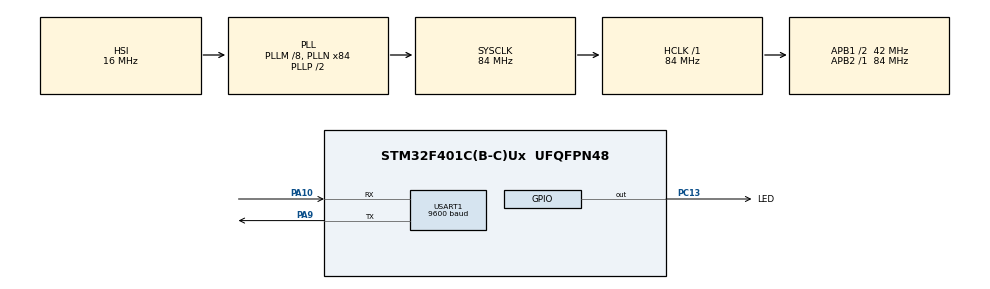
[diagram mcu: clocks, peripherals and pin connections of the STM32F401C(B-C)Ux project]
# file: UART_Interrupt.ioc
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Mcu.Family=STM32F4
RCC.CortexFreq_Value=84000000
PA10.Mode=Asynchronous
PC13-ANTI_TAMP.GPIO_Label=LED
USART1.BaudRate=9600
PH1\ -\ OSC_OUT.Mode=HSE-External-Oscillator
RCC.APB1CLKDivider=RCC_HCLK_DIV2
PC13-ANTI_TAMP.PinState=GPIO_PIN_SET
RCC.SYSCLKSource=RCC_SYSCLKSOURCE_PLLCLK
ProjectManager.StackSize=0x400
PA13.Signal=SYS_JTMS-SWDIO
PA9.Mode=Asynchronous
PH0\ -\ OSC_IN.Mode=HSE-External-Oscillator
VP_SYS_VS_tim10.Mode=TIM10
PH0\ -\ OSC_IN.Signal=RCC_OSC_IN
ProjectManager.TargetToolchain=STM32CubeIDE
RCC.HCLKFreq_Value=84000000
RCC.APB2TimFreq_Value=84000000
PA9.Signal=USART1_TX
RCC.LSE_VALUE=32768
RCC.AHBFreq_Value=84000000
RCC.HSE_VALUE=25000000
PH1\ -\ OSC_OUT.Signal=RCC_OSC_OUT
board=custom
PC13-ANTI_TAMP.Signal=GPIO_Output
RCC.VCOOutputFreq_Value=168000000
RCC.APB2Freq_Value=84000000
PA14.Mode=Serial_Wire
PA13.Mode=Serial_Wire
Mcu.Name=STM32F401C(B-C)Ux
RCC.48MHZClocksFreq_Value=42000000
RCC.SYSCLKFreq_VALUE=84000000
Mcu.Package=UFQFPN48
NVIC.TimeBase=TIM1_UP_TIM10_IRQn
USART1.VirtualMode=VM_ASYNC
NVIC.TimeBaseIP=TIM10
PA10.Signal=USART1_RX
PA14.Signal=SYS_JTCK-SWCLK
ProjectManager.HeapSize=0x200
NVIC.TIM1_UP_TIM10_IRQn=true\:0\:0\:false\:false\:true\:false\:true
RCC.HSI_VALUE=16000000
NVIC.PriorityGroup=NVIC_PRIORITYGROUP_4
RCC.PLLM=8
RCC.PLLN=84
RCC.APB1TimFreq_Value=84000000
NVIC.USART1_IRQn=true\:0\:0\:false\:false\:true\:true\:true
RCC.APB1Freq_Value=42000000

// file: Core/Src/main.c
/* USER CODE BEGIN Header */
/**
  ******************************************************************************
  * @file           : main.c
  * @brief          : Main program body
  ******************************************************************************
  * @attention
  *
  * <h2><center>&copy; Copyright (c) 2021 STMicroelectronics.
  * All rights reserved.</center></h2>
  *
  * This software component is licensed by ST under BSD 3-Clause license,
  * the "License"; You may not use this file except in compliance with the
  * License. You may obtain a copy of the License at:
  *                        opensource.org/licenses/BSD-3-Clause
  *
  ******************************************************************************
  */
/* USER CODE END Header */
#include "main.h"

/* USER CODE BEGIN Includes */
#include <stdio.h>
#include <string.h>
/* USER CODE END Includes */

UART_HandleTypeDef huart1;

/* USER CODE BEGIN PV */
uint8_t rxBuff[50];
/* USER CODE END PV */

void SystemClock_Config(void);
static void MX_GPIO_Init(void);
static void MX_USART1_UART_Init(void);
/* USER CODE BEGIN PFP */
void HAL_UART_RxCpltCallback(UART_HandleTypeDef *huart) {
	if(huart->Instance == huart1.Instance) {
		if(rxBuff[0] == 'o')
			HAL_GPIO_WritePin(LED_GPIO_Port, LED_Pin, GPIO_PIN_RESET);
		if(rxBuff[0] == 'x')
			HAL_GPIO_WritePin(LED_GPIO_Port, LED_Pin, GPIO_PIN_SET);
		HAL_UART_Receive_IT(&huart1, rxBuff, 1);
	}
}
/* USER CODE END PFP */

int main(void)
{

  /* MCU Configuration--------------------------------------------------------*/

  /* Reset of all peripherals, Initializes the Flash interface and the Systick. */
  HAL_Init();

  /* Configure the system clock */
  SystemClock_Config();

  /* Initialize all configured peripherals */
  MX_GPIO_Init();
  MX_USART1_UART_Init();
  /* USER CODE BEGIN 2 */
  char str[50];
  sprintf(str, "System running...\r\n");
  /* USER CODE END 2 */

  /* Infinite loop */
  /* USER CODE BEGIN WHILE */
  HAL_UART_Receive_IT(&huart1, rxBuff, 1);
  while (1)
  {
	HAL_UART_Transmit_IT(&huart1, (uint8_t*) str, strlen(str));
	HAL_Delay(500);
    /* USER CODE END WHILE */

  }
}

void SystemClock_Config(void)
{
  RCC_OscInitTypeDef RCC_OscInitStruct = {0};
  RCC_ClkInitTypeDef RCC_ClkInitStruct = {0};

  /** Configure the main internal regulator output voltage
  */
  __HAL_RCC_PWR_CLK_ENABLE();
  __HAL_PWR_VOLTAGESCALING_CONFIG(PWR_REGULATOR_VOLTAGE_SCALE2);
  /** Initializes the RCC Oscillators according to the specified parameters
  * in the RCC_OscInitTypeDef structure.
  */
  RCC_OscInitStruct.OscillatorType = RCC_OSCILLATORTYPE_HSI;
  RCC_OscInitStruct.HSIState = RCC_HSI_ON;
  RCC_OscInitStruct.HSICalibrationValue = RCC_HSICALIBRATION_DEFAULT;
  RCC_OscInitStruct.PLL.PLLState = RCC_PLL_ON;
  RCC_OscInitStruct.PLL.PLLSource = RCC_PLLSOURCE_HSI;
  RCC_OscInitStruct.PLL.PLLM = 8;
  RCC_OscInitStruct.PLL.PLLN = 84;
  RCC_OscInitStruct.PLL.PLLP = RCC_PLLP_DIV2;
  RCC_OscInitStruct.PLL.PLLQ = 4;
  if (HAL_RCC_OscConfig(&RCC_OscInitStruct) != HAL_OK)
  {
    Error_Handler();
  }
  /** Initializes the CPU, AHB and APB buses clocks
  */
  RCC_ClkInitStruct.ClockType = RCC_CLOCKTYPE_HCLK|RCC_CLOCKTYPE_SYSCLK
                              |RCC_CLOCKTYPE_PCLK1|RCC_CLOCKTYPE_PCLK2;
  RCC_ClkInitStruct.SYSCLKSource = RCC_SYSCLKSOURCE_PLLCLK;
  RCC_ClkInitStruct.AHBCLKDivider = RCC_SYSCLK_DIV1;
  RCC_ClkInitStruct.APB1CLKDivider = RCC_HCLK_DIV2;
  RCC_ClkInitStruct.APB2CLKDivider = RCC_HCLK_DIV1;

  if (HAL_RCC_ClockConfig(&RCC_ClkInitStruct, FLASH_LATENCY_2) != HAL_OK)
  {
    Error_Handler();
  }
}

static void MX_USART1_UART_Init(void)
{

  huart1.Instance = USART1;
  huart1.Init.BaudRate = 9600;
  huart1.Init.WordLength = UART_WORDLENGTH_8B;
  huart1.Init.StopBits = UART_STOPBITS_1;
  huart1.Init.Parity = UART_PARITY_NONE;
  huart1.Init.Mode = UART_MODE_TX_RX;
  huart1.Init.HwFlowCtl = UART_HWCONTROL_NONE;
  huart1.Init.OverSampling = UART_OVERSAMPLING_16;
  if (HAL_UART_Init(&huart1) != HAL_OK)
  {
    Error_Handler();
  }

}

static void MX_GPIO_Init(void)
{
  GPIO_InitTypeDef GPIO_InitStruct = {0};

  /* GPIO Ports Clock Enable */
  __HAL_RCC_GPIOC_CLK_ENABLE();
  __HAL_RCC_GPIOH_CLK_ENABLE();
  __HAL_RCC_GPIOA_CLK_ENABLE();

  /*Configure GPIO pin Output Level */
  HAL_GPIO_WritePin(LED_GPIO_Port, LED_Pin, GPIO_PIN_SET);

  /*Configure GPIO pin : LED_Pin */
  GPIO_InitStruct.Pin = LED_Pin;
  GPIO_InitStruct.Mode = GPIO_MODE_OUTPUT_PP;
  GPIO_InitStruct.Pull = GPIO_NOPULL;
  GPIO_InitStruct.Speed = GPIO_SPEED_FREQ_LOW;
  HAL_GPIO_Init(LED_GPIO_Port, &GPIO_InitStruct);

}

 /**
  * @brief  Period elapsed callback in non blocking mode
  * @note   This function is called  when TIM10 interrupt took place, inside
  * HAL_TIM_IRQHandler(). It makes a direct call to HAL_IncTick() to increment
  * a global variable "uwTick" used as application time base.
  * @param  htim : TIM handle
  * @retval None
  */
void HAL_TIM_PeriodElapsedCallback(TIM_HandleTypeDef *htim)
{
  if (htim->Instance == TIM10) {
    HAL_IncTick();
  }
}

void Error_Handler(void)
{
  __disable_irq();
  while (1)
  {
  }
}

/************************ (C) COPYRIGHT STMicroelectronics *****END OF FILE****/
